# iND83216 register map
Vendor: Indiemicro; Series: RealplumTiny; File version: 1.00
CPU: CM0 r0p1, selectable endian, no MPU, no FPU, 4 interrupt priority bits
Registers are 32-bit, read-write, no defined reset value unless marked. A register's access mark holds for its fields unless they carry their own. Offsets are from the block's base; [hi:lo] are bit positions.

## FLASH — Control (and status) registers for FMC
Base 0x50021000; register names take the prefix FLASH_
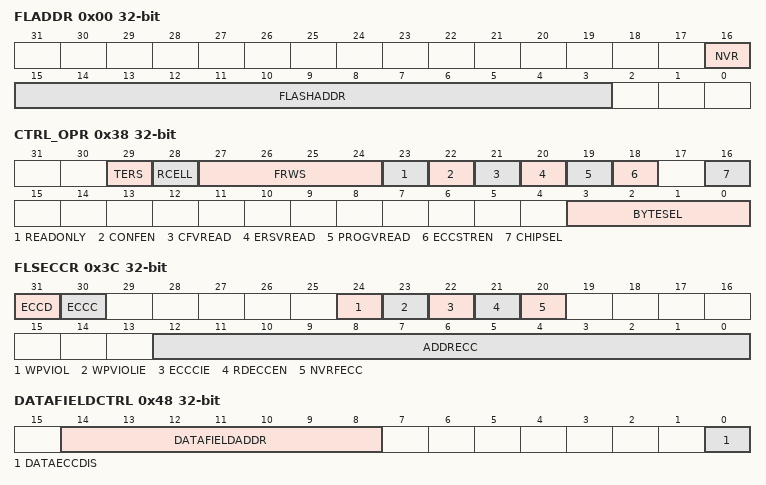
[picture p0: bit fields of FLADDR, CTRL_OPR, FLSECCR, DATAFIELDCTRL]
0x00 FLADDR — Destination address for flash write or erase operation
  [16] NVR — NVR indication for write/erase operation.
  [15:3] FLASHADDR — Target flash line for write/erase operation. In byte writes, this is the line address of the flash to be written to. In erase modes, it is an address inside the sector to be erased. NOTE:This register must be written in the correct sequence or the operation will fail.
0x04 DATALR — Data (least-significant word)
  [31:0] DATAL — Data (least-significant word). The least-significant, 32-bit word of data that will be written to Flash
0x08 DATAMR — Data (most-significant word)
  [31:0] DATAM — Data (most-significant word). The most-significant, 32-bit word of data that will be written to Flash
0x0C ECCVALR — ECC value and status
  [7:0] ECCVAL — ECC value. If ECCSTREN = 1, 8bit redundant bits will be stored into ECCVAL during each flash fetch operation. NOTE:If RDECCEN = 1, this field may be corrected by ECC algorithm. During programming ECCVAL will be copied to the 8bit redundant bits of a Flash word. This field will update by syndrome code generated by ECC encoder when DATAM is written with 32-bit data. This field can still be updated by software after hardware update, through this method we can implement raw data program into flash 72bit line.
0x10 UNLBWR — Flash write unlock register
  [31:0] UNLOCK_WRITE — Control register to unlock write. A value of 0x55555555 must be written to this address at the correct point in the write sequence or the operation will fail. Bit 0 will be set if 0x55555555 is written, and will be clear if write operation is started successfully or any other value is written the this register. Other bits read return zero.
0x14 BWRSTRTR — Flash write start register
  [31:0] WRITE_START wo — Control register to start a write. A value of 0xAAAAAAAA or 0x502901FF (program to NVR1) must be written to this address at the correct point in the write sequence or the operation will fail. Read return zero.
0x18 UNLERSR — Flash erase unlock register
  [31:0] UNLOCK_ERASE — Control register to unlock a erase operation. A value of 0x66666666 must be written to this address at the correct point in the erase sequence or the operation will fail. Bit 0 will be set if 0x66666666 is written, and will be clear if erase operation is started successfully or any other value is written the this register. Other bits read return zero.
0x1C ERSSTRTR — Flash erase start register
  [31:0] ERASE_START wo — Control register to commit a sector erase. A value of 0x99999999 or 0x502901FF (Sector erase to NVR1) must be written to this address at the correct point in the sector erase sequence or the operation will fail. Read return zero.
0x20 FLSCPR — Flash code protection register
  [31:0] CODE_PROT — Code Protection / SerialWire Lockout Control Write a value of 0xF2E11047 to disable the SerialWire interface. Write other values will enable it. This allows the user program to disable the SerialWire interface to prevent unauthorized debug access to the part. Bit 0 will be set if 0xF2E11047 is written, and will be clear if any other value is written the this register. Other bits read return zero. NOTE1: This register does not lock the Flash Memory against read/write/erase by the applications program. Instead what it does is to disable all communications with the debug interface, therefore preventing any external attack. The application code is still able to modify the flash content. NOTE2: Upon Power-On Reset or Normal Reset the system disables the communication for a small time interval (8192 clock cycles). If the application needs to be protected it is mandatory to set this register with the appropriate code in the beginning of the initialization process and before the internal hardware enable the debug communication. NOTE3: Program 0xF2E11047 in last Flash address(low 32 bits of 8Bytes) of Main Memory can also realize Code Protection.
0x24 FLSWPKEYR — Flash write protection key register
  [31:0] WPKEY — Flash write pretection key for FLSWPx to take effect. A value of 0x12100511 must be written to this address to allow FLSWP0 and FLSWP1 to take effect. Once FLSWPx have taken effect it will be locked for safety. Bit 0 will be set if 0x12100511 is written, and can only be cleared by system reset. Other bits read return zero.
0x28 FLSWP0R — Flash write protection 0 register
  [31:0] FLSWP0 — Flash write protection field protect one kilo byte by one bit. Bit0 protect the first KB, bit1 for the second KB, ... NOTE: This field only take effect after correct key has been written to FLSWPKEYR. And this field can not be modified after taking effect.
0x2C FLSWP1R — Flash write protection 1 register
  [31:0] FLSWP1 — Flash write protection field protect one kilo byte by one bit. Bit0 protects the 33th KB, bit1 for the 34th KB, ... NOTE: This field only take effect after correct key has been written to FLSWPKEYR. And this field can not be modified after taking effect.
0x30 FLSWP2R — Flash write protection 2 register
  [0] FLSWPNVR — Flash write protection field for NVR sectors. FLSWPNVR protects the first and the second NVR sector NOTE: This field only take effect after correct key has been written to FLSWPKEYR. And this field can not be modified after taking effect.
0x34 FLS_UNLOCK_CTRL_OPR — Flash Unlock Control Operation Register
  [31:0] UNLOCK_CTRL_OP — Flash Control Operation Register Unlock value. 0xACDC_1972 needs to be written in this register to unlock the Control Operation Register access. When this register is read, it returns the state of the lock: 0: The Control Operation Register is locked. The CHIPSEL bit of FLASH_CTRL_OPR cannot be written. 1: The Control Operation Register is unlocked. The CHIPSEL bit of FLASH_CTRL_OPR can be written. NOTE: After each write to the third byte of FLASH_CTRL_OPR register, the state of the lock is cleared and the pattern needs to be written again to allow a new configuration of the register.
0x38 CTRL_OPR — Flash Control Operation Register
  [29] TERS — Transfer cell erase operation. TERS=1 only for transfer cell initialization for Flash IP without CP testing. TERS=0 for other cases.
  [28] RCELL — Reference cell selected operation. RCELL =1 only for reference cell initialization for Flash IP without CP testing. RCELL =0 for other cases.
  [27:24] FRWS — Flash Read Wait State Number. Number of wait states used in the reading process. Each read from flash memory will take number of cycles equal to 1+FRWS to complete. NOTE:FRWS = 2 is adequate for normal read. When in margin read, make sure (1 + FRWS ) * Fhclk is slower than 225ns.
  [23] READONLY — Read only enable. Only can do read operation to Flash, disable program and erase function .the program or erase operation will be aborted immediately if enable READONLY.
  [22] CONFEN — Set configuration registers. To write configuration data to registers
  [21] CFVREAD — READ configuration registers. To read registers’ configuration data to DOUT for check
  [20] ERSVREAD — Erase Margin Read Enable. Set to enable margin read for erase cell verification. NOTE:After set ERSVREAD, must wait one cycle to issued new flash read to execute erase margin read.
  [19] PROGVREAD — Program Margin Read Enable. Set to enable margin read for program cell verification. NOTE:After set PROGVREAD, must wait one cycle to issued new flash read to execute program margin read.
  [18] ECCSTREN — ECC Store Enable. When set, 8bit redundant bits will be stored into ECCVAL during every flash fetch operation.
  [16] CHIPSEL — CHIP selection bit. This bit is only used during the Erase operation. It allows the system to execute mass erase. 0: The Erase operation will only erase the sector selected by the FLASH_ADDR register value. 1: The Erase operation will erase the full main array of the flash. NOTE:CHIPSEL can only be written when bit-0 of FLS_UNLOCK_CTRL_OPR is set.
  [3:0] BYTESEL — Byte selection of the write operation. Set to 1 indicated the corresponding 2Bytes will be programmed. NOTE1: This register is only used in debug mode, and locked by debug_key. In function mode, 8Bytes need to be programmed together. NOTE2: BYTESEL's set bits must be continuous, otherwise will cause unintentional chaos. ex. 4'b1100, 4'b0110, 4'b0011, 4'b1000 are valid setting, 4'b1011, 4'b1001 are not allowed.
0x3C FLSECCR — Flash ECC Register
  [31] ECCD — ECC detection. Set by hardware when two ECC errors has been detected. When this bit is set, a NMI is generated. Cleared by writing 1.
  [30] ECCC — ECC correction. Set by hardware when one ECC error has been detected and corrected. An interrupt is generated if ECCIE is set. Cleared by writing 1.
  [24] WPVIOL — Write Protection Violation. Set by hardware when flash write protection has been violated. An interrupt is generated if WPVIOLIE is set. Cleared by writing 1.
  [23] WPVIOLIE — Write Protection Violation interrupt enable. 0x0: WPVIOL interrupt disabled0x1: WPVIOL interrupt enabled
  [22] ECCCIE — ECC correction interrupt enable. 0x0: ECCC interrupt disabled0x1: ECCC interrupt enabled
  [21] RDECCEN — Read ECC correction and detection Enable. ECC correction and detection will only be enabled when RDECCEN is set.
  [20] NVRFECC ro — NVR ECC fail. This bit indicates that the ECC error correction or double ECC error detection is located in the NVR Flash memory.
  [12:0] ADDRECC ro — ECC fail double-word address offset. In case of ECC error or ECC correction detected, this bitfield contains double-word offset (multiple of 64 bits) to Main Flash memory or to NVR1.
0x40 TRIM — Flash Trim Register
  [7:0] OSC_TRIM — Oscillator Trim Value. This register will be automatically populated with the value stored in the least significant bits of NVR sector 1 (@0002_0000).
0x44 FLSSTATR — Flash Status Register
  [8] OPBSY ro — Flash operatoin busy indication. Reading 1 indicate program/erase operation busy. NOTE: In the SWD erase operation, OPBSY may be started 256 cycles later after command issued.
0x48 DATAFIELDCTRL — Flash data field with optional ecc register
  [14:8] DATAFIELDADDR — Flash data field base address. Flash data field base address. DATAFIELDADDR = 0 represent DATA field start at the 1st sector of main array, DATAFIELDADDR = 127 represent DATA field start at the last sector of main array,and ends at the end address of the 128th sector
  [0] DATAECCDIS — 0x0: ECC for data field enabled0x1: ECC for data field disabled
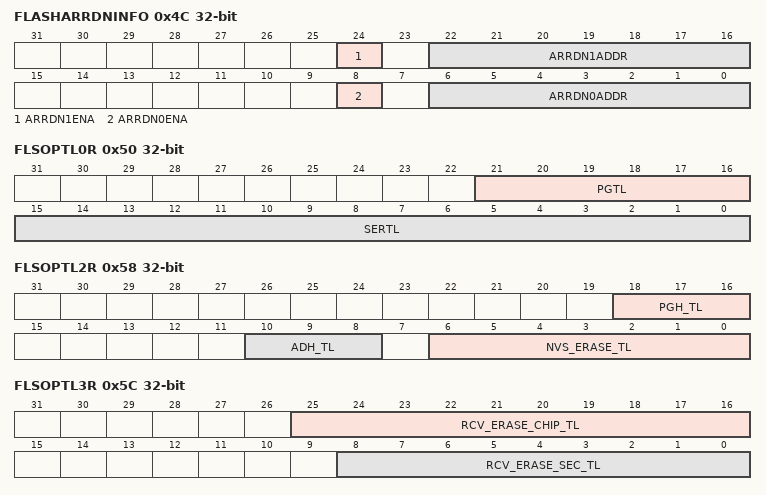
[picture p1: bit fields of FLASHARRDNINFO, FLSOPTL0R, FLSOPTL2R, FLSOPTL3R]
0x4C FLASHARRDNINFO — FLASH Redundancy Sector Information Registers
  [24] ARRDN1ENA ro — FLASH ARRDN1 Sector Enable.
  [22:16] ARRDN1ADDR ro — FLASH ARRND1 Sector Address.
  [8] ARRDN0ENA ro — FLASH ARRDN0 Sector Enable.
  [6:0] ARRDN0ADDR ro — FLASH ARRND0 Sector Address.
0x50 FLSOPTL0R — Flash Operation Time Length 0 Register
  [21:16] PGTL — Program Time Length. This register define the duration of byte program operation in number of 4M oscillator's cycles. Default duration is 5750ns
  [15:0] SERTL — Sector Erase Time Length. This register define the duration of sector erase operation in number of 4M oscillator's cycles. Default duration is 4.5ms
0x54 FLSOPTL1R — Flash Operation Time Length 1 Register
  [17:0] MERTL — Chip Mass Erase Time Length. This register define the duration of chip mass erase operation in number of 4M oscillator's cycles. Default duration is 35ms
0x58 FLSOPTL2R — Flash Operation Time Length 2 Register
  [18:16] PGH_TL — Program Fall of PROG2 to fall of WE Hold time. This register define the Hold time of PROG2's fall to WE's fall operation in number of 4M oscillator's cycles. Default duration is 0.75us
  [10:8] ADH_TL — Program BYTE/Address/data Hold time. This register define the hold time of BYTE/Address/data operation in number of 4M oscillator's cycles. Default duration is 0.75us
  [6:0] NVS_ERASE_TL — Sector Erase ERASE/CE/NVR to WE Setup time. This register define the setup time from ERASE/CE/NVR to WE operation in number of 4M oscillator's cycles. Default duration is 25us
0x5C FLSOPTL3R — Flash Operation Time Length 3 Register
  [25:16] RCV_ERASE_CHIP_TL — Sector Erase Recovery time. This register define the setup time from WE fall to ERASE fall operation in number of 4M oscillator's cycles. Default duration is 230us
  [8:0] RCV_ERASE_SEC_TL — Sector Erase Recovery time. This register define the setup time from WE fall to ERASE fall operation in number of 4M oscillator's cycles. Default duration is 60us
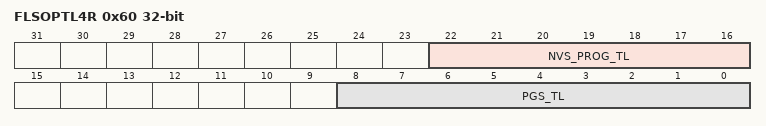
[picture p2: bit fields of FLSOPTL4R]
0x60 FLSOPTL4R — Flash Operation Time Length 4 Register, load from NVR at first
  [22:16] NVS_PROG_TL — Program PROG/CE/NVR/BYTE/Address to WE Setup time. This register define the setup time from PROG/CE/NVR/BYTE[0:3]/Address to WE operation in number of 4M oscillator's cycles. Default duration is 25us
  [8:0] PGS_TL — Program Rise of WE to rise of PROG2 Setup time. This register define the setup time from rise of WE to rise of PROG2 operation in number of 4M oscillator's cycles. Default duration is 60us
0x64 FLSOPTL5R — Flash Operation Time Length 5 Register, load from NVR at first
  [8:0] RCV_PROG_TL — Program Recovery time. This register define the setup time from WE fall to PROG fall operation in number of 4M oscillator's cycles. Default duration is 60us
